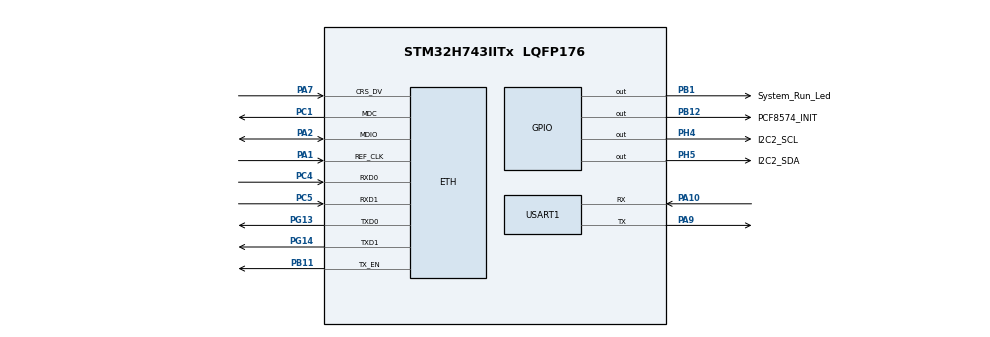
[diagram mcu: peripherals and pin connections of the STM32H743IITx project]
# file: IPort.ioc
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CORTEX_M7.AccessPermission_S-Cortex_Memory_Protection_Unit_Region1_Settings_S=MPU_REGION_FULL_ACCESS
CORTEX_M7.AccessPermission_Spec=MPU_REGION_FULL_ACCESS
CORTEX_M7.BaseAddress_S-Cortex_Memory_Protection_Unit_Region1_Settings_S=0x30044000
CORTEX_M7.BaseAddress_Spec=0x30040000
CORTEX_M7.CPU_DCache=Enabled
CORTEX_M7.CPU_ICache=Enabled
CORTEX_M7.DisableExec_Spec=MPU_INSTRUCTION_ACCESS_ENABLE
CORTEX_M7.Enable_S-Cortex_Memory_Protection_Unit_Region1_Settings_S=MPU_REGION_ENABLE
CORTEX_M7.IsBufferable_S-Cortex_Memory_Protection_Unit_Region1_Settings_S=MPU_ACCESS_NOT_BUFFERABLE
CORTEX_M7.IsBufferable_Spec=MPU_ACCESS_BUFFERABLE
CORTEX_M7.IsCacheable_S-Cortex_Memory_Protection_Unit_Region1_Settings_S=MPU_ACCESS_CACHEABLE
CORTEX_M7.IsCacheable_Spec=MPU_ACCESS_NOT_CACHEABLE
CORTEX_M7.IsShareable_S-Cortex_Memory_Protection_Unit_Region1_Settings_S=MPU_ACCESS_NOT_SHAREABLE
CORTEX_M7.IsShareable_Spec=MPU_ACCESS_NOT_SHAREABLE
CORTEX_M7.Size_S-Cortex_Memory_Protection_Unit_Region1_Settings_S=MPU_REGION_SIZE_16KB
CORTEX_M7.Size_Spec=MPU_REGION_SIZE_256B
CORTEX_M7.SubRegionDisable_Spec=0x0
CORTEX_M7.default_mode_Activation=1
Dma.Request0=USART1_RX
Dma.Request1=USART1_TX
Dma.USART1_RX.0.Direction=DMA_PERIPH_TO_MEMORY
Dma.USART1_RX.0.EventEnable=DISABLE
Dma.USART1_RX.0.FIFOMode=DMA_FIFOMODE_DISABLE
Dma.USART1_RX.0.Instance=DMA1_Stream0
Dma.USART1_RX.0.MemDataAlignment=DMA_MDATAALIGN_BYTE
Dma.USART1_RX.0.MemInc=DMA_MINC_ENABLE
Dma.USART1_RX.0.Mode=DMA_CIRCULAR
Dma.USART1_RX.0.PeriphDataAlignment=DMA_PDATAALIGN_BYTE
Dma.USART1_RX.0.PeriphInc=DMA_PINC_DISABLE
Dma.USART1_RX.0.Polarity=HAL_DMAMUX_REQ_GEN_RISING
Dma.USART1_RX.0.Priority=DMA_PRIORITY_LOW
Dma.USART1_RX.0.RequestNumber=1
Dma.USART1_RX.0.SignalID=NONE
Dma.USART1_RX.0.SyncEnable=DISABLE
Dma.USART1_RX.0.SyncPolarity=HAL_DMAMUX_SYNC_NO_EVENT
Dma.USART1_RX.0.SyncRequestNumber=1
Dma.USART1_RX.0.SyncSignalID=NONE
Dma.USART1_TX.1.Direction=DMA_MEMORY_TO_PERIPH
Dma.USART1_TX.1.EventEnable=DISABLE
Dma.USART1_TX.1.FIFOMode=DMA_FIFOMODE_DISABLE
Dma.USART1_TX.1.Instance=DMA1_Stream1
Dma.USART1_TX.1.MemDataAlignment=DMA_MDATAALIGN_BYTE
Dma.USART1_TX.1.MemInc=DMA_MINC_ENABLE
Dma.USART1_TX.1.Mode=DMA_NORMAL
Dma.USART1_TX.1.PeriphDataAlignment=DMA_PDATAALIGN_BYTE
Dma.USART1_TX.1.PeriphInc=DMA_PINC_DISABLE
Dma.USART1_TX.1.Polarity=HAL_DMAMUX_REQ_GEN_RISING
Dma.USART1_TX.1.Priority=DMA_PRIORITY_LOW
Dma.USART1_TX.1.RequestNumber=1
Dma.USART1_TX.1.SignalID=NONE
Dma.USART1_TX.1.SyncEnable=DISABLE
Dma.USART1_TX.1.SyncPolarity=HAL_DMAMUX_SYNC_NO_EVENT
Dma.USART1_TX.1.SyncRequestNumber=1
Dma.USART1_TX.1.SyncSignalID=NONE
ETH.MediaInterface=HAL_ETH_RMII_MODE
ETH.RxDescAddress=0x30040000
ETH.TxDescAddress=0x30040060
FREERTOS.INCLUDE_uxTaskGetStackHighWaterMark=1
FREERTOS.INCLUDE_vTaskDelayUntil=1
FREERTOS.Tasks01=defaultTask,0,256,StartDefaultTask,Default,NULL,Dynamic,NULL,NULL
FREERTOS.configENABLE_FPU=1
FREERTOS.configGENERATE_RUN_TIME_STATS=1
FREERTOS.configMINIMAL_STACK_SIZE=128
FREERTOS.configTOTAL_HEAP_SIZE=20480
FREERTOS.configUSE_COUNTING_SEMAPHORES=0
FREERTOS.configUSE_MALLOC_FAILED_HOOK=1
FREERTOS.configUSE_STATS_FORMATTING_FUNCTIONS=1
FREERTOS.configUSE_TICK_HOOK=1
FREERTOS.configUSE_TRACE_FACILITY=1
LWIP.BSP.number=1
LWIP.CHECKSUM_BY_HARDWARE=0
LWIP.GATEWAY_ADDRESS=010.012.019.001
LWIP.IP_ADDRESS=010.012.019.252
LWIP.LWIP_CHECKSUM_CTRL_PER_NETIF=1
LWIP.LWIP_DHCP=0
LWIP.LWIP_MPU_COMPATIBLE=1
LWIP.MEMP_MEM_INIT=0
LWIP.MEMP_MEM_MALLOC=0
LWIP.MEMP_NUM_PBUF=100
LWIP.MEMP_NUM_TCP_PCB=10
LWIP.MEMP_NUM_UDP_PCB=20
LWIP.MEM_LIBC_MALLOC=0
LWIP.MEM_SIZE=1024*10
LWIP.NETMASK_ADDRESS=255.255.255.000
LWIP.Version=v2.1.2_Cube
LWIP0.BSP.STBoard=false
LWIP0.BSP.api=BSP_COMPONENT_DRIVER
LWIP0.BSP.component=LAN8742
LWIP0.BSP.instance=LAN8742
LWIP0.BSP.name=Driver_PHY
LWIP0.BSP.semaphore=S_LAN8742
LWIP0.BSP.solution=LAN8742
Mcu.Family=STM32H7
Mcu.Name=STM32H743IITx
Mcu.Package=LQFP176
NVIC.DMA1_Stream1_IRQn=true\:5\:0\:false\:false\:true\:true\:true\:true\:true
NVIC.ETH_IRQn=true\:5\:0\:false\:false\:true\:true\:true\:true\:true
NVIC.PriorityGroup=NVIC_PRIORITYGROUP_4
NVIC.TIM7_IRQn=true\:15\:0\:false\:false\:true\:false\:false\:true\:true
NVIC.TimeBase=TIM7_IRQn
NVIC.TimeBaseIP=TIM7
NVIC.USART1_IRQn=true\:5\:0\:false\:false\:true\:true\:true\:true\:true
PA1.GPIO_Speed=GPIO_SPEED_FREQ_VERY_HIGH
PA1.Mode=RMII
PA1.Signal=ETH_REF_CLK
PA10.GPIO_Speed=GPIO_SPEED_FREQ_VERY_HIGH
PA10.Mode=Asynchronous
PA10.Signal=USART1_RX
PA2.GPIO_Speed=GPIO_SPEED_FREQ_VERY_HIGH
PA2.Mode=RMII
PA2.Signal=ETH_MDIO
PA7.GPIO_Speed=GPIO_SPEED_FREQ_VERY_HIGH
PA7.Mode=RMII
PA7.Signal=ETH_CRS_DV
PA9.GPIO_Speed=GPIO_SPEED_FREQ_VERY_HIGH
PA9.Mode=Asynchronous
PA9.Signal=USART1_TX
PB1.GPIO_Label=System_Run_Led
PB1.Signal=GPIO_Output
PB11.GPIO_Speed=GPIO_SPEED_FREQ_VERY_HIGH
PB11.Mode=RMII
PB11.Signal=ETH_TX_EN
PB12.GPIO_Label=PCF8574_INIT
PB12.Signal=GPIO_Output
PC1.GPIO_Speed=GPIO_SPEED_FREQ_VERY_HIGH
PC1.Mode=RMII
PC1.Signal=ETH_MDC
PC14-OSC32_IN\ (OSC32_IN).Mode=LSE-External-Oscillator
PC14-OSC32_IN\ (OSC32_IN).Signal=RCC_OSC32_IN
PC15-OSC32_OUT\ (OSC32_OUT).Mode=LSE-External-Oscillator
PC15-OSC32_OUT\ (OSC32_OUT).Signal=RCC_OSC32_OUT
PC4.GPIO_Speed=GPIO_SPEED_FREQ_VERY_HIGH
PC4.Mode=RMII
PC4.Signal=ETH_RXD0
PC5.GPIO_Speed=GPIO_SPEED_FREQ_VERY_HIGH
PC5.Mode=RMII
PC5.Signal=ETH_RXD1
PG13.GPIO_Speed=GPIO_SPEED_FREQ_VERY_HIGH
PG13.Mode=RMII
PG13.Signal=ETH_TXD0
PG14.GPIO_Speed=GPIO_SPEED_FREQ_VERY_HIGH
PG14.Mode=RMII
PG14.Signal=ETH_TXD1
PH0-OSC_IN\ (PH0).Mode=HSE-External-Oscillator
PH0-OSC_IN\ (PH0).Signal=RCC_OSC_IN
PH1-OSC_OUT\ (PH1).Mode=HSE-External-Oscillator
PH1-OSC_OUT\ (PH1).Signal=RCC_OSC_OUT
PH4.GPIO_Label=I2C2_SCL
PH4.GPIO_PuPd=GPIO_PULLUP
PH4.GPIO_Speed=GPIO_SPEED_FREQ_VERY_HIGH
PH4.Signal=GPIO_Output
PH5.GPIO_Label=I2C2_SDA
PH5.GPIO_ModeDefaultOutputPP=GPIO_MODE_OUTPUT_OD
PH5.GPIO_PuPd=GPIO_PULLUP
PH5.GPIO_Speed=GPIO_SPEED_FREQ_VERY_HIGH
PH5.Signal=GPIO_Output
ProjectManager.HeapSize=0x2000
ProjectManager.StackSize=0x1000
ProjectManager.TargetToolchain=MDK-ARM V5.32
RCC.ADCFreq_Value=50390625
RCC.APB1Freq_Value=120000000
RCC.APB2Freq_Value=120000000
RCC.APB3Freq_Value=120000000
RCC.APB4Freq_Value=120000000
RCC.CortexFreq_Value=480000000
RCC.D1PPRE=RCC_APB3_DIV2
RCC.D2PPRE1=RCC_APB1_DIV2
RCC.D2PPRE2=RCC_APB2_DIV2
RCC.D3PPRE=RCC_APB4_DIV2
RCC.DIVM1=5
RCC.DIVN1=192
RCC.HCLKFreq_Value=240000000
RCC.HPRE=RCC_HCLK_DIV2
RCC.PLLSourceVirtual=RCC_PLLSOURCE_HSE
RCC.PWR_Regulator_Voltage_Scale=PWR_REGULATOR_VOLTAGE_SCALE0
RCC.ProductRev=revV
RCC.RCC_TIM_PRescaler_Selection=RCC_TIMPRES_DESACTIVATED
RCC.SYSCLKFreq_VALUE=480000000
RCC.SYSCLKSource=RCC_SYSCLKSOURCE_PLLCLK
RCC.SupplySource=PWR_LDO_SUPPLY
RCC.USBFreq_Value=480000000
USART1.VirtualMode-Asynchronous=VM_ASYNC
VP_FREERTOS_VS_CMSIS_V1.Mode=CMSIS_V1
VP_LWIP_VS_Enabled.Mode=Enabled
VP_SYS_VS_tim7.Mode=TIM7
board=custom

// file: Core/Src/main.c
/* USER CODE BEGIN Header */
/**
  ******************************************************************************
  * @file           : main.c
  * @brief          : Main program body
  ******************************************************************************
  * @attention
  *
  * Copyright (c) 2023 STMicroelectronics.
  * All rights reserved.
  *
  * This software is licensed under terms that can be found in the LICENSE file
  * in the root directory of this software component.
  * If no LICENSE file comes with this software, it is provided AS-IS.
  *
  ******************************************************************************
  */
/* USER CODE END Header */
#include "main.h"
#include "cmsis_os.h"
#include "dma.h"
#include "lwip.h"
#include "usart.h"
#include "gpio.h"

/* USER CODE BEGIN Includes */
#include "os_init.h"
#include "g_init.h"
/* USER CODE END Includes */

void SystemClock_Config(void);
static void MPU_Config(void);
void MX_FREERTOS_Init(void);

int main(void)
{
  /* USER CODE BEGIN 1 */
	do{ *(__IO uint32_t*)0XE000EF9C = 1UL << 2; }while(0);	/* Cache透写模式 */
  /* USER CODE END 1 */

  /* MPU Configuration--------------------------------------------------------*/
  MPU_Config();

  /* Enable I-Cache---------------------------------------------------------*/
  SCB_EnableICache();

  /* Enable D-Cache---------------------------------------------------------*/
  SCB_EnableDCache();

  /* MCU Configuration--------------------------------------------------------*/

  /* Reset of all peripherals, Initializes the Flash interface and the Systick. */
  HAL_Init();

  /* USER CODE BEGIN Init */
	SCB->CACR |= 1 << 2;//* 强制D-Cache透写,如不开启透写,实际使用中可能遇到各种问题 */
  /* USER CODE END Init */

  /* Configure the system clock */
  SystemClock_Config();

  /* Initialize all configured peripherals */
  MX_GPIO_Init();
  MX_DMA_Init();
  MX_USART1_UART_Init();
  /* USER CODE BEGIN 2 */
    g_Init();
    Os_Init();
  /* USER CODE END 2 */

  /* Call init function for freertos objects (in freertos.c) */
  MX_FREERTOS_Init();

  /* Start scheduler */
  osKernelStart();
  /* We should never get here as control is now taken by the scheduler */
  /* Infinite loop */
    while (1)
    {

    }
}

void SystemClock_Config(void)
{
  RCC_OscInitTypeDef RCC_OscInitStruct = {0};
  RCC_ClkInitTypeDef RCC_ClkInitStruct = {0};

  /** Supply configuration update enable
  */
  HAL_PWREx_ConfigSupply(PWR_LDO_SUPPLY);

  /** Configure the main internal regulator output voltage
  */
  __HAL_PWR_VOLTAGESCALING_CONFIG(PWR_REGULATOR_VOLTAGE_SCALE1);

  while(!__HAL_PWR_GET_FLAG(PWR_FLAG_VOSRDY)) {}

  __HAL_RCC_SYSCFG_CLK_ENABLE();
  __HAL_PWR_VOLTAGESCALING_CONFIG(PWR_REGULATOR_VOLTAGE_SCALE0);

  while(!__HAL_PWR_GET_FLAG(PWR_FLAG_VOSRDY)) {}

  /** Initializes the RCC Oscillators according to the specified parameters
  * in the RCC_OscInitTypeDef structure.
  */
  RCC_OscInitStruct.OscillatorType = RCC_OSCILLATORTYPE_HSE;
  RCC_OscInitStruct.HSEState = RCC_HSE_ON;
  RCC_OscInitStruct.PLL.PLLState = RCC_PLL_ON;
  RCC_OscInitStruct.PLL.PLLSource = RCC_PLLSOURCE_HSE;
  RCC_OscInitStruct.PLL.PLLM = 5;
  RCC_OscInitStruct.PLL.PLLN = 192;
  RCC_OscInitStruct.PLL.PLLP = 2;
  RCC_OscInitStruct.PLL.PLLQ = 2;
  RCC_OscInitStruct.PLL.PLLR = 2;
  RCC_OscInitStruct.PLL.PLLRGE = RCC_PLL1VCIRANGE_2;
  RCC_OscInitStruct.PLL.PLLVCOSEL = RCC_PLL1VCOWIDE;
  RCC_OscInitStruct.PLL.PLLFRACN = 0;
  if (HAL_RCC_OscConfig(&RCC_OscInitStruct) != HAL_OK)
  {
    Error_Handler();
  }

  /** Initializes the CPU, AHB and APB buses clocks
  */
  RCC_ClkInitStruct.ClockType = RCC_CLOCKTYPE_HCLK|RCC_CLOCKTYPE_SYSCLK
                              |RCC_CLOCKTYPE_PCLK1|RCC_CLOCKTYPE_PCLK2
                              |RCC_CLOCKTYPE_D3PCLK1|RCC_CLOCKTYPE_D1PCLK1;
  RCC_ClkInitStruct.SYSCLKSource = RCC_SYSCLKSOURCE_PLLCLK;
  RCC_ClkInitStruct.SYSCLKDivider = RCC_SYSCLK_DIV1;
  RCC_ClkInitStruct.AHBCLKDivider = RCC_HCLK_DIV2;
  RCC_ClkInitStruct.APB3CLKDivider = RCC_APB3_DIV2;
  RCC_ClkInitStruct.APB1CLKDivider = RCC_APB1_DIV2;
  RCC_ClkInitStruct.APB2CLKDivider = RCC_APB2_DIV2;
  RCC_ClkInitStruct.APB4CLKDivider = RCC_APB4_DIV2;

  if (HAL_RCC_ClockConfig(&RCC_ClkInitStruct, FLASH_LATENCY_4) != HAL_OK)
  {
    Error_Handler();
  }
}

/* MPU Configuration */

void MPU_Config(void)
{
  MPU_Region_InitTypeDef MPU_InitStruct = {0};

  /* Disables the MPU */
  HAL_MPU_Disable();

  /** Initializes and configures the Region and the memory to be protected
  */
  MPU_InitStruct.Enable = MPU_REGION_ENABLE;
  MPU_InitStruct.Number = MPU_REGION_NUMBER0;
  MPU_InitStruct.BaseAddress = 0x30040000;
  MPU_InitStruct.Size = MPU_REGION_SIZE_256B;
  MPU_InitStruct.SubRegionDisable = 0x0;
  MPU_InitStruct.TypeExtField = MPU_TEX_LEVEL0;
  MPU_InitStruct.AccessPermission = MPU_REGION_FULL_ACCESS;
  MPU_InitStruct.DisableExec = MPU_INSTRUCTION_ACCESS_ENABLE;
  MPU_InitStruct.IsShareable = MPU_ACCESS_NOT_SHAREABLE;
  MPU_InitStruct.IsCacheable = MPU_ACCESS_NOT_CACHEABLE;
  MPU_InitStruct.IsBufferable = MPU_ACCESS_BUFFERABLE;

  HAL_MPU_ConfigRegion(&MPU_InitStruct);

  /** Initializes and configures the Region and the memory to be protected
  */
  MPU_InitStruct.Number = MPU_REGION_NUMBER1;
  MPU_InitStruct.BaseAddress = 0x30044000;
  MPU_InitStruct.Size = MPU_REGION_SIZE_16KB;
  MPU_InitStruct.IsCacheable = MPU_ACCESS_CACHEABLE;
  MPU_InitStruct.IsBufferable = MPU_ACCESS_NOT_BUFFERABLE;

  HAL_MPU_ConfigRegion(&MPU_InitStruct);
  /* Enables the MPU */
  HAL_MPU_Enable(MPU_PRIVILEGED_DEFAULT);

}

void HAL_TIM_PeriodElapsedCallback(TIM_HandleTypeDef *htim)
{
  if (htim->Instance == TIM7) {
    HAL_IncTick();
  }
}

void Error_Handler(void)
{
    __disable_irq();
    while (1)
    {
    }
}

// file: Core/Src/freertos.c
/* USER CODE BEGIN Header */
/**
  ******************************************************************************
  * File Name          : freertos.c
  * Description        : Code for freertos applications
  ******************************************************************************
  * @attention
  *
  * Copyright (c) 2023 STMicroelectronics.
  * All rights reserved.
  *
  * This software is licensed under terms that can be found in the LICENSE file
  * in the root directory of this software component.
  * If no LICENSE file comes with this software, it is provided AS-IS.
  *
  ******************************************************************************
  */
/* USER CODE END Header */

#include "FreeRTOS.h"
#include "task.h"
#include "main.h"
#include "cmsis_os.h"

osThreadId defaultTaskHandle;

void StartDefaultTask(void const * argument);

extern void MX_LWIP_Init(void);
void MX_FREERTOS_Init(void); /* (MISRA C 2004 rule 8.1) */

/* GetIdleTaskMemory prototype (linked to static allocation support) */
void vApplicationGetIdleTaskMemory( StaticTask_t **ppxIdleTaskTCBBuffer, StackType_t **ppxIdleTaskStackBuffer, uint32_t *pulIdleTaskStackSize );

/* Hook prototypes */
void configureTimerForRunTimeStats(void);
unsigned long getRunTimeCounterValue(void);
void vApplicationTickHook(void);
void vApplicationMallocFailedHook(void);

/* USER CODE BEGIN 1 */
/* Functions needed when configGENERATE_RUN_TIME_STATS is on */
__weak void configureTimerForRunTimeStats(void)
{

}

__weak unsigned long getRunTimeCounterValue(void)
{
return 0;
}
/* USER CODE END 1 */

/* USER CODE BEGIN 3 */
__weak void vApplicationTickHook( void )
{
   /* This function will be called by each tick interrupt if
   configUSE_TICK_HOOK is set to 1 in FreeRTOSConfig.h. User code can be
   added here, but the tick hook is called from an interrupt context, so
   code must not attempt to block, and only the interrupt safe FreeRTOS API
   functions can be used (those that end in FromISR()). */
}
/* USER CODE END 3 */

/* USER CODE BEGIN 5 */
__weak void vApplicationMallocFailedHook(void)
{
   /* vApplicationMallocFailedHook() will only be called if
   configUSE_MALLOC_FAILED_HOOK is set to 1 in FreeRTOSConfig.h. It is a hook
   function that will get called if a call to pvPortMalloc() fails.
   pvPortMalloc() is called internally by the kernel whenever a task, queue,
   timer or semaphore is created. It is also called by various parts of the
   demo application. If heap_1.c or heap_2.c are used, then the size of the
   heap available to pvPortMalloc() is defined by configTOTAL_HEAP_SIZE in
   FreeRTOSConfig.h, and the xPortGetFreeHeapSize() API function can be used
   to query the size of free heap space that remains (although it does not
   provide information on how the remaining heap might be fragmented). */
}
/* USER CODE END 5 */

/* USER CODE BEGIN GET_IDLE_TASK_MEMORY */
static StaticTask_t xIdleTaskTCBBuffer;
static StackType_t xIdleStack[configMINIMAL_STACK_SIZE];

void vApplicationGetIdleTaskMemory( StaticTask_t **ppxIdleTaskTCBBuffer, StackType_t **ppxIdleTaskStackBuffer, uint32_t *pulIdleTaskStackSize )
{
  *ppxIdleTaskTCBBuffer = &xIdleTaskTCBBuffer;
  *ppxIdleTaskStackBuffer = &xIdleStack[0];
  *pulIdleTaskStackSize = configMINIMAL_STACK_SIZE;
  /* place for user code */
}
/* USER CODE END GET_IDLE_TASK_MEMORY */

void MX_FREERTOS_Init(void) {

  /* Create the thread(s) */
  /* definition and creation of defaultTask */
  osThreadDef(defaultTask, StartDefaultTask, osPriorityNormal, 0, 256);
  defaultTaskHandle = osThreadCreate(osThread(defaultTask), NULL);

}

void StartDefaultTask(void const * argument)
{
  /* init code for LWIP */
  MX_LWIP_Init();
  for(;;)
  {
    osDelay(1);
  }
}
